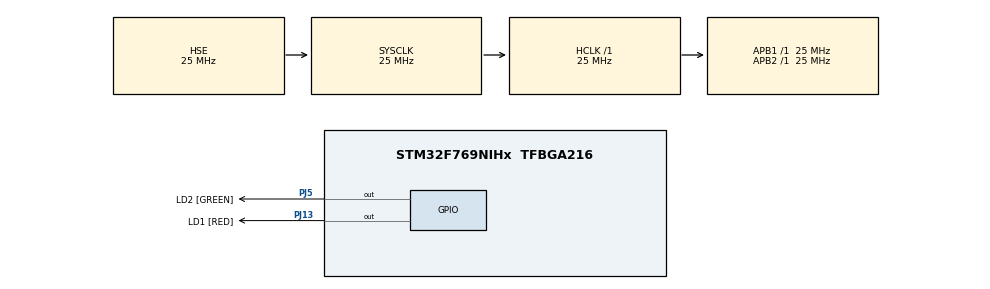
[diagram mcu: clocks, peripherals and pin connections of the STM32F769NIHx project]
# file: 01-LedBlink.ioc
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Mcu.Family=STM32F7
Mcu.Name=STM32F769NIHx
Mcu.Package=TFBGA216
NVIC.PriorityGroup=NVIC_PRIORITYGROUP_4
PA13.Mode=Serial_Wire
PA13.Signal=SYS_JTMS-SWDIO
PA14.Mode=Serial_Wire
PA14.Signal=SYS_JTCK-SWCLK
PH0/OSC_IN.Mode=HSE-External-Oscillator
PH0/OSC_IN.Signal=RCC_OSC_IN
PH1/OSC_OUT.Mode=HSE-External-Oscillator
PH1/OSC_OUT.Signal=RCC_OSC_OUT
PJ13.GPIO_Label=LD1 [RED]
PJ13.Signal=GPIO_Output
PJ5.GPIO_Label=LD2 [GREEN]
PJ5.Signal=GPIO_Output
ProjectManager.HeapSize=0x200
ProjectManager.StackSize=0x400
ProjectManager.TargetToolchain=EWARM V8
RCC.AHBFreq_Value=25000000
RCC.APB1Freq_Value=25000000
RCC.APB1TimFreq_Value=25000000
RCC.APB2Freq_Value=25000000
RCC.APB2TimFreq_Value=25000000
RCC.CortexFreq_Value=25000000
RCC.HCLKFreq_Value=25000000
RCC.HSE_VALUE=25000000
RCC.HSI_VALUE=16000000
RCC.LSE_VALUE=32768
RCC.PLLSourceVirtual=RCC_PLLSOURCE_HSE
RCC.SYSCLKFreq_VALUE=25000000
RCC.SYSCLKSource=RCC_SYSCLKSOURCE_HSE
RCC.USBFreq_Value=150000000
RCC.VCOOutputFreq_Value=300000000
board=custom

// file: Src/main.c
/* USER CODE BEGIN Header */
/**
  ******************************************************************************
  * @file           : main.c
  * @brief          : Main program body
  ******************************************************************************
  * @attention
  *
  * <h2><center>&copy; Copyright (c) 2020 STMicroelectronics.
  * All rights reserved.</center></h2>
  *
  * This software component is licensed by ST under BSD 3-Clause license,
  * the "License"; You may not use this file except in compliance with the
  * License. You may obtain a copy of the License at:
  *                        opensource.org/licenses/BSD-3-Clause
  *
  ******************************************************************************
  */
/* USER CODE END Header */

#include "main.h"

/* USER CODE BEGIN PM */
#define LED_1_TASK_TIME       2000u   /* In milliseconds */
#define LED_2_TASK_TIME       1000u   /* In milliseconds */
/* USER CODE END PM */

/* USER CODE BEGIN PV */
uint8_t led_1_state = FALSE;
uint8_t led_2_state = FALSE;
uint32_t led_1_timestamp = 0u;
uint32_t led_2_timestamp = 0u;
/* USER CODE END PV */

void SystemClock_Config(void);
static void MX_GPIO_Init(void);

int main(void)
{

  /* MCU Configuration--------------------------------------------------------*/

  /* Reset of all peripherals, Initializes the Flash interface and the Systick. */
  HAL_Init();

  /* Configure the system clock */
  SystemClock_Config();

  /* Initialize all configured peripherals */
  MX_GPIO_Init();
  /* USER CODE BEGIN 2 */
  led_1_timestamp = HAL_GetTick();
  led_2_timestamp = HAL_GetTick();
  /* USER CODE END 2 */

  /* Infinite loop */
  while (1)
  {

    /* USER CODE BEGIN 3 */
    /* Method-1: Simple Way of Blinking */
//    HAL_GPIO_TogglePin( LD1_GPIO_Port, LD1_Pin);
//    HAL_GPIO_TogglePin( LD2_GPIO_Port, LD2_Pin);
//    HAL_Delay(500);

    /* Method-2: With the help of SysTick timers*/
    /* Task for Led 1 */
    if( HAL_GetTick() - led_1_timestamp > LED_1_TASK_TIME )
    {
      led_1_timestamp = HAL_GetTick();
      if( led_1_state )
      {
        led_1_state = FALSE;
        /* Setting Pin High will turn off the Led */
        HAL_GPIO_WritePin( LD1_GPIO_Port, LD1_Pin, GPIO_PIN_SET );
      }
      else
      {
        led_1_state = TRUE;
        /* Setting Pin Low will turn on the Led */
        HAL_GPIO_WritePin( LD1_GPIO_Port, LD1_Pin, GPIO_PIN_RESET );
      }
    }
    /* Task for Led 2 */
    if( HAL_GetTick() - led_2_timestamp > LED_2_TASK_TIME )
    {
      led_2_timestamp = HAL_GetTick();
      if( led_2_state )
      {
        led_2_state = FALSE;
        /* Setting Pin High will turn off the Led */
        HAL_GPIO_WritePin( LD2_GPIO_Port, LD2_Pin, GPIO_PIN_SET );
      }
      else
      {
        led_2_state = TRUE;
        /* Setting Pin Low will turn on the Led */
        HAL_GPIO_WritePin( LD2_GPIO_Port, LD2_Pin, GPIO_PIN_RESET );
      }
    }
  }
  /* USER CODE END 3 */
}

void SystemClock_Config(void)
{
  RCC_OscInitTypeDef RCC_OscInitStruct = {0};
  RCC_ClkInitTypeDef RCC_ClkInitStruct = {0};

  /** Configure the main internal regulator output voltage
  */
  __HAL_RCC_PWR_CLK_ENABLE();
  __HAL_PWR_VOLTAGESCALING_CONFIG(PWR_REGULATOR_VOLTAGE_SCALE3);
  /** Initializes the CPU, AHB and APB busses clocks
  */
  RCC_OscInitStruct.OscillatorType = RCC_OSCILLATORTYPE_HSE;
  RCC_OscInitStruct.HSEState = RCC_HSE_ON;
  RCC_OscInitStruct.PLL.PLLState = RCC_PLL_NONE;
  if (HAL_RCC_OscConfig(&RCC_OscInitStruct) != HAL_OK)
  {
    Error_Handler();
  }
  /** Initializes the CPU, AHB and APB busses clocks
  */
  RCC_ClkInitStruct.ClockType = RCC_CLOCKTYPE_HCLK|RCC_CLOCKTYPE_SYSCLK
                              |RCC_CLOCKTYPE_PCLK1|RCC_CLOCKTYPE_PCLK2;
  RCC_ClkInitStruct.SYSCLKSource = RCC_SYSCLKSOURCE_HSE;
  RCC_ClkInitStruct.AHBCLKDivider = RCC_SYSCLK_DIV1;
  RCC_ClkInitStruct.APB1CLKDivider = RCC_HCLK_DIV1;
  RCC_ClkInitStruct.APB2CLKDivider = RCC_HCLK_DIV1;

  if (HAL_RCC_ClockConfig(&RCC_ClkInitStruct, FLASH_LATENCY_0) != HAL_OK)
  {
    Error_Handler();
  }
}

static void MX_GPIO_Init(void)
{
  GPIO_InitTypeDef GPIO_InitStruct = {0};

  /* GPIO Ports Clock Enable */
  __HAL_RCC_GPIOA_CLK_ENABLE();
  __HAL_RCC_GPIOJ_CLK_ENABLE();
  __HAL_RCC_GPIOH_CLK_ENABLE();

  /*Configure GPIO pin Output Level */
  HAL_GPIO_WritePin(GPIOJ, LD1_Pin|LD2_Pin, GPIO_PIN_RESET);

  /*Configure GPIO pins : LD1_Pin LD2_Pin */
  GPIO_InitStruct.Pin = LD1_Pin|LD2_Pin;
  GPIO_InitStruct.Mode = GPIO_MODE_OUTPUT_PP;
  GPIO_InitStruct.Pull = GPIO_NOPULL;
  GPIO_InitStruct.Speed = GPIO_SPEED_FREQ_LOW;
  HAL_GPIO_Init(GPIOJ, &GPIO_InitStruct);

}

void Error_Handler(void)
{
}

/************************ (C) COPYRIGHT STMicroelectronics *****END OF FILE****/
